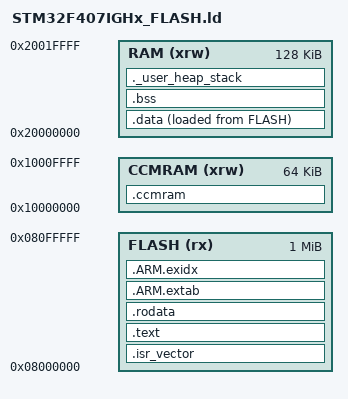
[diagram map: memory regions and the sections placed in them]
/**
 * STM32F407IGHx_FLASH.ld
 * Linker script for STM32F407IGHx (1MB Flash, 128KB SRAM + 64KB CCM)
 */
MEMORY
{
  FLASH  (rx)  : ORIGIN = 0x08000000, LENGTH = 1024K
  RAM    (xrw) : ORIGIN = 0x20000000, LENGTH = 128K
  CCMRAM (xrw) : ORIGIN = 0x10000000, LENGTH = 64K
}

_estack = ORIGIN(RAM) + LENGTH(RAM);

ENTRY(Reset_Handler)

SECTIONS
{
  .isr_vector :
  {
    KEEP(*(.isr_vector))
    . = ALIGN(4);
  } > FLASH

  .text :
  {
    . = ALIGN(4);
    *(.text)
    *(.text*)
    *(.glue_7)
    *(.glue_7t)
    *(.eh_frame)
    KEEP(*(.init))
    KEEP(*(.fini))
    . = ALIGN(4);
    _etext = .;
  } > FLASH

  .rodata :
  {
    . = ALIGN(4);
    *(.rodata)
    *(.rodata*)
    . = ALIGN(4);
  } > FLASH

  .ARM.extab :
  {
    . = ALIGN(4);
    *(.ARM.extab* .gnu.linkonce.armextab.*)
    . = ALIGN(4);
  } > FLASH

  .ARM.exidx :
  {
    . = ALIGN(4);
    PROVIDE(__exidx_start = .);
    *(.ARM.exidx* .gnu.linkonce.armexidx.*)
    PROVIDE(__exidx_end = .);
    . = ALIGN(4);
  } > FLASH

  _sidata = LOADADDR(.data);

  .data :
  {
    . = ALIGN(4);
    _sdata = .;
    *(.data)
    *(.data*)
    . = ALIGN(4);
    _edata = .;
  } > RAM AT> FLASH

  .bss :
  {
    . = ALIGN(4);
    _sbss = .;
    __bss_start__ = _sbss;
    *(.bss)
    *(.bss*)
    *(COMMON)
    . = ALIGN(4);
    _ebss = .;
    __bss_end__ = _ebss;
  } > RAM

  ._user_heap_stack :
  {
    . = ALIGN(8);
    PROVIDE(end = .);
    PROVIDE(_end = .);
    . = . + _Min_Heap_Size;
    . = . + _Min_Stack_Size;
    . = ALIGN(8);
  } > RAM

  /* CCMRAM — core-coupled memory, used by FreeRTOS tasks optionally */
  .ccmram (NOLOAD) :
  {
    . = ALIGN(4);
    *(.ccmram)
    *(.ccmram*)
    . = ALIGN(4);
  } > CCMRAM
}

_Min_Heap_Size  = 0x2000;   /* 8KB heap */
_Min_Stack_Size = 0x2000;   /* 8KB main stack */
